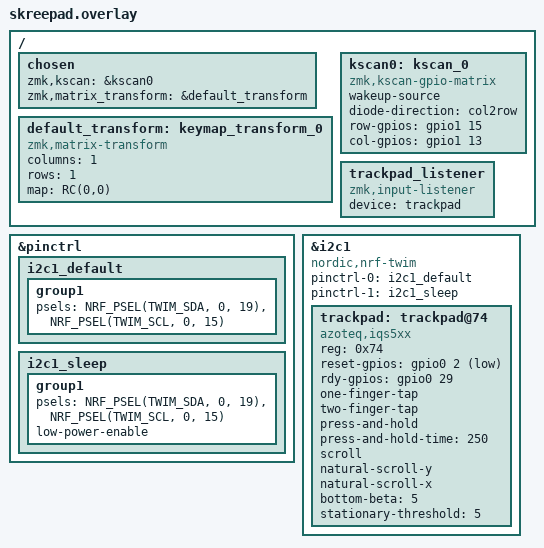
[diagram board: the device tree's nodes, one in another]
#include <dt-bindings/zmk/matrix_transform.h>

/ {
    chosen {
        zmk,kscan = &kscan0;
        zmk,matrix_transform = &default_transform;
    };

    default_transform: keymap_transform_0 {
        compatible = "zmk,matrix-transform";
        columns = <1>;
        rows = <1>;
        map = <RC(0,0)>;
    };

    kscan0: kscan_0 {
        compatible = "zmk,kscan-gpio-matrix";
        wakeup-source;
        diode-direction = "col2row";

        row-gpios = <&gpio1 15 (GPIO_ACTIVE_HIGH | GPIO_PULL_DOWN)>;
        col-gpios = <&gpio1 13 GPIO_ACTIVE_HIGH>;
    };

    trackpad_listener: trackpad_listener {
        compatible = "zmk,input-listener";
        device = <&trackpad>;
    };
};

&pinctrl {
    i2c1_default: i2c1_default {
        group1 {
            psels = <NRF_PSEL(TWIM_SDA, 0, 19)>,
                    <NRF_PSEL(TWIM_SCL, 0, 15)>;
        };
    };

    i2c1_sleep: i2c1_sleep {
        group1 {
            psels = <NRF_PSEL(TWIM_SDA, 0, 19)>,
                    <NRF_PSEL(TWIM_SCL, 0, 15)>;
            low-power-enable;
        };
    };
};

&i2c1 {
    status = "okay";
    compatible = "nordic,nrf-twim";
    pinctrl-0 = <&i2c1_default>;
    pinctrl-1 = <&i2c1_sleep>;
    pinctrl-names = "default", "sleep";

    trackpad: trackpad@74 {
        status = "okay";
        compatible = "azoteq,iqs5xx";
        reg = <0x74>;
        reset-gpios = <&gpio0 2 GPIO_ACTIVE_LOW>;
        rdy-gpios = <&gpio0 29 GPIO_ACTIVE_HIGH>;

        // Gesture support
        one-finger-tap;
        two-finger-tap;
        press-and-hold;
        press-and-hold-time = <250>;

        // Scroll support
        scroll;
        natural-scroll-y;
        natural-scroll-x;

        // Tuning parameters
        bottom-beta = <5>;
        stationary-threshold = <5>;
    };
};
